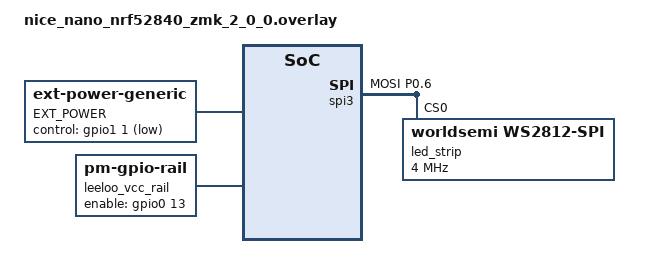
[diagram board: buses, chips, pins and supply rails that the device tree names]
/*
 * Copyright (c) 2026 Clickety Split Ltd.
 * SPDX-License-Identifier: MIT
 */

#include <dt-bindings/gpio/gpio.h>
#include <dt-bindings/led/led.h>

/ {
    chosen {
        zmk,underglow = &led_strip;
    };

    EXT_POWER {
        compatible = "zmk,ext-power-generic";
        control-gpios = <&gpio1 1 GPIO_ACTIVE_LOW>;
        init-delay-ms = <1>;
    };
};

/ {
    leeloo_vcc_rail: leeloo-vcc-rail {
        compatible = "zmk,pm-gpio-rail";
        enable-gpios = <&gpio0 13 GPIO_ACTIVE_HIGH>;
        init-delay-ms = <50>;
        status = "okay";
    };
};

&pinctrl {
    spi3_default: spi3_default {
        group1 {
            psels = <NRF_PSEL(SPIM_MOSI, 0, 6)>;
        };
    };

    spi3_sleep: spi3_sleep {
        group1 {
            psels = <NRF_PSEL(SPIM_MOSI, 0, 6)>;
            low-power-enable;
        };
    };
};

&spi3 {
    compatible = "nordic,nrf-spim";
    status = "okay";

    pinctrl-0 = <&spi3_default>;
    pinctrl-1 = <&spi3_sleep>;
    pinctrl-names = "default", "sleep";

    led_strip: ws2812@0 {
        compatible = "worldsemi,ws2812-spi";

        reg = <0>;
        spi-max-frequency = <4000000>;

        chain-length = <29>;
        spi-one-frame = <0x70>;
        spi-zero-frame = <0x40>;

        color-mapping = <
            LED_COLOR_ID_GREEN
            LED_COLOR_ID_RED
            LED_COLOR_ID_BLUE
        >;
    };
};

/* Leeloo-owned Sharp memory-in-pixel display wiring. */
#include "../../clickety_split_leeloo_rev3_nice_nano_v2_mip.dtsi"
